# PIC32CX2051BZ62132 register map
Vendor: Microchip Technology; Series: PIC32CXBZ62; File version: 0
CPU: CM4 r0p1, little endian, MPU, FPU, 3 interrupt priority bits, 58 interrupts
Registers are 32-bit, read-write, reset 0x0 unless marked. A register's access mark holds for its fields unless they carry their own. Offsets are from the block's base; [hi:lo] are bit positions; {n}, {i} and the like mark numbered series; 'fields as' and 'values as' point back to an identical list.

## CFG
Base 0x44000000
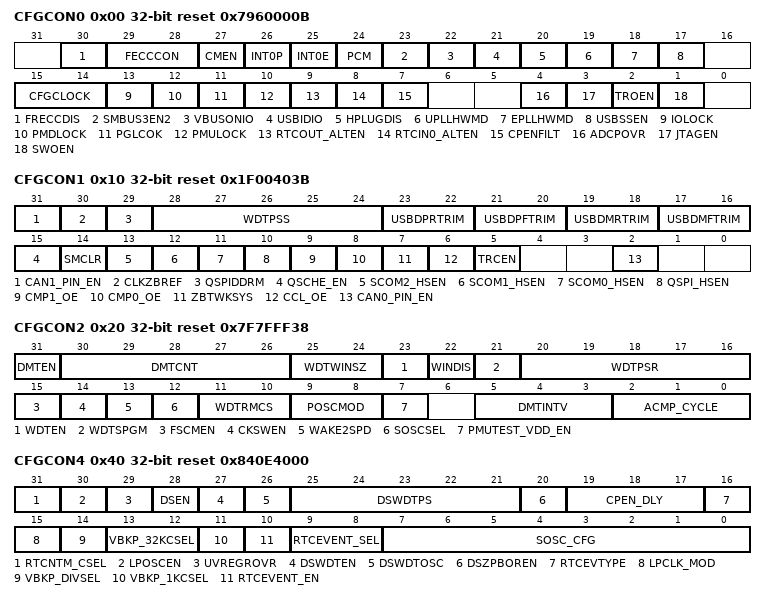
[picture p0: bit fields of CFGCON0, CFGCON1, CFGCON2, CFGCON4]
0x00 CFGCON0 reset 0x7960000B
  [30] FRECCDIS — Flex RAM ECC Control
  [29:28] FECCCON — Flash ECC Control
  [27] CMEN — SPA/DPA Countermeasures Enable
  [26] INT0P — INT0P Polarity
  [25] INT0E — INT0 Enable
  [24] PCM — PCHE I/D Cacheable Mode
  [23] SMBUS3EN2 — SMBus3 Enable for SERCOM2
  [22] VBUSONIO — USB VBUS_ON Selection bit
  [21] USBIDIO — USB USBID Selection bit
  [20] HPLUGDIS — Hot Plugging Disable (Outside Fuse Loading)
  [19] UPLLHWMD — UWPLL HW Control Mode for PWDN and RESET
  [18] EPLLHWMD — EWPLL HW Control Mode for PWDN and RESET
  [17] USBSSEN — USB Suspend Sleep Enable
  [15:14] CFGCLOCK — Configuration Register Lock
  [13] IOLOCK
  [12] PMDLOCK — Peripheral Module Disable (PMD) LOCK
  [11] PGLCOK — Permission Group LOCK
  [10] PMULOCK — PMU Controller Register LOCK
  [9] RTCOUT_ALTEN — RTCOUT Alternate Enable
  [8] RTCIN0_ALTEN — RTCIN0 Alternate Enable
  [7] CPENFILT — ADC CP Filter Enable
  [4] ADCPOVR — ADC Charge Pump Override
  [3] JTAGEN — JTAG Enable
  [2] TROEN — Trace Output Enable
  [1] SWOEN — SWO enable on 2-wire debug interface
{0x4+0x10*i} CFGCON{i}CLR (i=0..2) — Bit clear register
{0x8+0x10*i} CFGCON{i}SET (i=0..2) — Bit set register
{0xC+0x10*i} CFGCON{i}INV (i=0..2) — Bit invert register
0x10 CFGCON1 reset 0x1F00403B
  [31] CAN1_PIN_EN — CAN1 Pin Enable
  [30] CLKZBREF — External Reference Clock ZB Enable
  [29] QSPIDDRM — QSPI DDR Mode Clock Enable
  [28:24] WDTPSS — Watchdog Timer Post-scale Select Sleep
  [23:22] USBDPRTRIM — USB DP Rise Trim fuse bits
  [21:20] USBDPFTRIM — USB DP Fall Trim fuse bits
  [19:18] USBDMRTRIM — USB DM Rise Trim fuse bits
  [17:16] USBDMFTRIM — USB DM Fall Trim fuse bits
  [15] QSCHE_EN — QSPI Address Space Cache Attribute
  [14] SMCLR — Selects CRU handling of MCLR Control
  [13] SCOM2_HSEN — SERCOM2 Direct (High Speed) Pin Enable
  [12] SCOM1_HSEN — SERCOM1 Direct (High Speed) Pin Enable
  [11] SCOM0_HSEN — SERCOM0 Direct (High Speed) Pin Enable
  [10] QSPI_HSEN — QSPI (Direct) Enable
  [9] CMP1_OE — Analog Comparator-1 Output Enable
  [8] CMP0_OE — Analog Comparator-0 Output Enable
  [7] ZBTWKSYS — ZBT Subsystem External Wake-up source
  [6] CCL_OE — CCL Pads (via PPS) Output Enable
  [5] TRCEN — Trace Enable
  [2] CAN0_PIN_EN — CAN0 Pin Enable
0x20 CFGCON2 reset 0x7F7FFF38
  [31] DMTEN — Dead Man Timer Enable
  [30:26] DMTCNT — Dead Man Timer Count Select
  [25:24] WDTWINSZ — Watchdog Timer Window Size
  [23] WDTEN — Watchdog Timer Enable
  [22] WINDIS — Windowed Watchdog Timer Disable
  [21] WDTSPGM — Watchdog Timer Stop during Flash Programming
  [20:16] WDTPSR — Watchdog Timer Post-scale Select Run
  [15] FSCMEN — Fail-Safe Clock Monitor Enable
  [14] CKSWEN — Software Clock Switching Enable
  [13] WAKE2SPD — 2-Speed startup enabled in Sleep mode
  [12] SOSCSEL — SOSC Selection Configuration
  [11:10] WDTRMCS — WDT RUN Mode Clock Select
  [9:8] POSCMOD — Primary Oscillator Configuration
  [7] PMUTEST_VDD_EN — PMU Test Output or VDD/2 Enable via ADC IE12
  [5:3] DMTINTV — Dead Man Timer Count Window Interval
  [2:0] ACMP_CYCLE — AC SIB Comparator Result Wait Cycles
0x40 CFGCON4 reset 0x840E4000
  [31] RTCNTM_CSEL — RTC Counter Mode Clock Select
  [30] LPOSCEN — Low Power (Secondary) Oscillator Enable
  [29] UVREGROVR — ULPVREG Retention Mode Override
  [28] DSEN — Deep Sleep Bit Enable
  [27] DSWDTEN — Deep Sleep Watchdog Timer Enable
  [26] DSWDTOSC — Deep Sleep Watchdog Timer Reference Clock Select
  [25:21] DSWDTPS — Deep Sleep Watchdog Timer Postscale Select
  [20] DSZPBOREN — Deep Sleep Zero-Power BOR Enable
  [19:17] CPEN_DLY — Charge-pump ready digital delay
  [16] RTCEVTYPE — RTC Event Type
  [15] LPCLK_MOD — LPCLK modifier in counter/delay mode
  [14] VBKP_DIVSEL — VDDBUKPCORE LPCLK Clock Divider Selection
  [13:12] VBKP_32KCSEL — VDDBUKPCORE 32KHz clock source selection
  [11] VBKP_1KCSEL — VDDBUKPCORE LPCLK Clock Selection
  [10] RTCEVENT_EN — Pad Output Enable for MCHP legacy RTC event output
  [9:8] RTCEVENT_SEL — RTC Event Selection
  [7:0] SOSC_CFG — SOSC Configuration
0x44 CFGCON4CLR — Bit clear register
0x48 CFGCON4SET — Bit set register
0x4C CFGCON4INV — Bit invert register
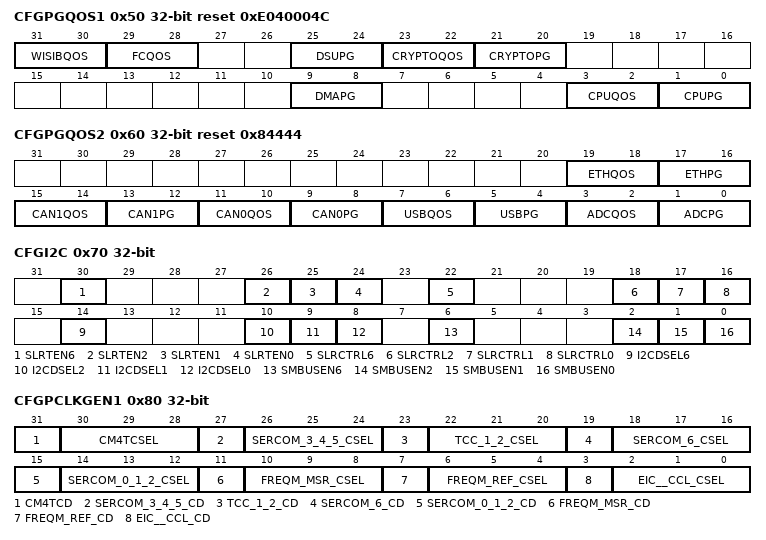
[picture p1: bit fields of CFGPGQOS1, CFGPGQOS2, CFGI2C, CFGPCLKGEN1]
0x50 CFGPGQOS1 reset 0xE040004C
  [31:30] WISIBQOS — Wireless SIB QOS Control
  [29:28] FCQOS — FC Controller QOS Control
  [25:24] DSUPG — DSU Permission Group
  [23:22] CRYPTOQOS — Crypto QOS Control
  [21:20] CRYPTOPG — Crypto Permission Group
  [9:8] DMAPG — DMA (Rd/Wr) Permission Group
  [3:2] CPUQOS — CPU I/D and System Bus QOS Control
  [1:0] CPUPG — CPU (Code) Permission Group
0x54 CFGPGQOS1CLR — Bit clear register
0x58 CFGPGQOS1SET — Bit set register
0x5C CFGPGQOS1INV — Bit invert register
0x60 CFGPGQOS2 reset 0x84444
  [19:18] ETHQOS — ETH QOS Control bits
  [17:16] ETHPG — ETH Permission Group
  [15:14] CAN1QOS — CAN1 QOS Control bits
  [13:12] CAN1PG — CAN1 Permission Group
  [11:10] CAN0QOS — CAN0 QOS Control bits
  [9:8] CAN0PG — CAN0 Permission Group
  [7:6] USBQOS — USB QOS Control bits
  [5:4] USBPG — USB Permission Group
  [3:2] ADCQOS — ADC QOS Control bits
  [1:0] ADCPG — ADC Permission Group
0x64 CFGPGQOS2CLR — Bit clear register
0x68 CFGPGQOS2SET — Bit set register
0x6C CFGPGQOS2INV — Bit invert register
0x70 CFGI2C
  [30] SLRTEN6 — SLRT Enable for SERCOM6
  [26] SLRTEN2 — SLRT Enable for SERCOM2
  [25] SLRTEN1 — SLRT Enable for SERCOM1
  [24] SLRTEN0 — SLRT Enable for SERCOM0
  [22] SLRCTRL6 — I2C Slew Rate Control for SERCOM6
  [18] SLRCTRL2 — I2C Slew Rate Control for SERCOM2
  [17] SLRCTRL1 — I2C Slew Rate Control for SERCOM1
  [16] SLRCTRL0 — I2C Slew Rate Control for SERCOM0
  [14] I2CDSEL6 — I2C Delay Select for SERCOM6
  [10] I2CDSEL2 — I2C Delay Select for SERCOM2
  [9] I2CDSEL1 — I2C Delay Select for SERCOM1
  [8] I2CDSEL0 — I2C Delay Select for SERCOM0
  [6] SMBUSEN6 — SMBus Enable for SERCOM6
  [2] SMBUSEN2 — SMBus Enable for SERCOM2
  [1] SMBUSEN1 — SMBus Enable for SERCOM1
  [0] SMBUSEN0 — SMBus Enable for SERCOM0
0x74 CFGI2CCLR — Bit clear register
0x78 CFGI2CSET — Bit set register
0x7C CFGI2CINV — Bit invert register
0x80 CFGPCLKGEN1
  [31] CM4TCD — CM4T Clock Disable
    1=ON (Enable PGCLK); 0=OFF (Disable PGCLK)
  [30:28] CM4TCSEL — CM4T Clock Selection
    0=NO_CLK (No Clock); {v}=REFO{v} (Reference Clock {v}) (v=1..6); 7=LPCLK (32 KHz Low Power Clock)
  [27] SERCOM_3_4_5_CD — SERCOM3/4/5 Clock Disable
    1=ON (Enable PGCLK); 0=OFF (Disable PGCLK)
  [26:24] SERCOM_3_4_5_CSEL — SERCOM3/4/5 Clock Selection
    values as CM4TCSEL
  [23] TCC_1_2_CD — TCC1/2 Clock Disable
    1=ON (Enable PGCLK); 0=OFF (Disable PGCLK)
  [22:20] TCC_1_2_CSEL — TCC1/2 Clock Selection
    values as CM4TCSEL
  [19] SERCOM_6_CD — SERCOM6 Clock Disable
    1=ON (Enable PGCLK); 0=OFF (Disable PGCLK)
  [18:16] SERCOM_6_CSEL — SERCOM6 Clock Selection
    values as CM4TCSEL
  [15] SERCOM_0_1_2_CD — SERCOM0/1/2 Clock Disable
    1=ON (Enable PGCLK); 0=OFF (Disable PGCLK)
  [14:12] SERCOM_0_1_2_CSEL — SERCOM0/1/2 Clock Selection
    values as CM4TCSEL
  [11] FREQM_MSR_CD — FREQMMC Clock Disable
    1=ON (Enable PGCLK); 0=OFF (Disable PGCLK)
  [10:8] FREQM_MSR_CSEL — FREQMMC Clock Selection
    values as CM4TCSEL
  [7] FREQM_REF_CD — FREQMRC Clock Disable
    1=ON (Enable PGCLK); 0=OFF (Disable PGCLK)
  [6:4] FREQM_REF_CSEL — FREQMRC Clock Selection
    values as CM4TCSEL
  [3] EIC__CCL_CD — EIC/CCL Clock Disable
    1=ON (Enable PGCLK); 0=OFF (Disable PGCLK)
  [2:0] EIC__CCL_CSEL — EIC/CCL Clock Selection
    values as CM4TCSEL
{0x74+0x10*i} CFGPCLKGEN{i}CLR (i=1..4) — Bit clear register
{0x78+0x10*i} CFGPCLKGEN{i}SET (i=1..4) — Bit set register
{0x7C+0x10*i} CFGPCLKGEN{i}INV (i=1..4) — Bit invert register
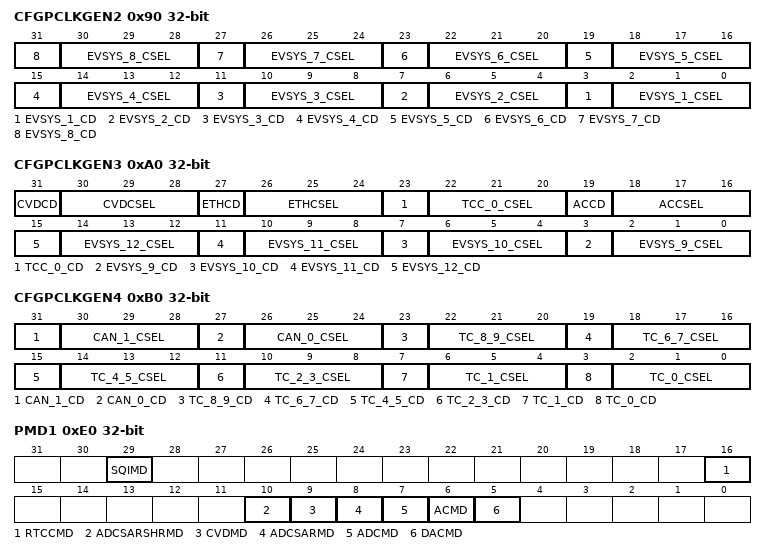
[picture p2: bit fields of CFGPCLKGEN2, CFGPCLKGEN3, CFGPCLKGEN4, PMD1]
0x90 CFGPCLKGEN2
  [4n-1] EVSYS_{n}_CD (n=1..8) — EVSYSC{n} Clock Disable
    1=ON (Enable PGCLK); 0=OFF (Disable PGCLK)
  [4n-2:4n-4] EVSYS_{n}_CSEL (n=1..8) — EVSYSC{n} Peripheral Clock Selection
    values as CFGPCLKGEN1.CM4TCSEL
0xA0 CFGPCLKGEN3
  [31] CVDCD — CVD Clock Disable
    1=ON (Enable PGCLK); 0=OFF (Disable PGCLK)
  [30:28] CVDCSEL — CVD Selection
    values as CFGPCLKGEN1.CM4TCSEL
  [27] ETHCD — Ethernet Clock Disable
    1=ON (Enable PGCLK); 0=OFF (Disable PGCLK)
  [26:24] ETHCSEL — Ethernet Clock Selection
    values as CFGPCLKGEN1.CM4TCSEL
  [23] TCC_0_CD — TCC0 Clock Disable
    1=ON (Enable PGCLK); 0=OFF (Disable PGCLK)
  [22:20] TCC_0_CSEL — TCC0 Peripheral Clock Selection
    values as CFGPCLKGEN1.CM4TCSEL
  [19] ACCD — AC Clock Disable
    1=ON (Enable PGCLK); 0=OFF (Disable PGCLK)
  [18:16] ACCSEL — AC Peripheral Clock Selection
    values as CFGPCLKGEN1.CM4TCSEL
  [4n-33] EVSYS_{n}_CD (n=9..12) — EVSYSC{n} Clock Disable
    1=ON (Enable PGCLK); 0=OFF (Disable PGCLK)
  [4n-34:4n-36] EVSYS_{n}_CSEL (n=9..12) — EVSYSC{n} Peripheral Clock Selection
    values as CFGPCLKGEN1.CM4TCSEL
0xB0 CFGPCLKGEN4
  [31] CAN_1_CD — CAN1 Clock Disable
    1=ON (Enable PGCLK); 0=OFF (Disable PGCLK)
  [30:28] CAN_1_CSEL — CAN1 Clock Selection
    values as CFGPCLKGEN1.CM4TCSEL
  [27] CAN_0_CD — CAN0 Clock Disable
    1=ON (Enable PGCLK); 0=OFF (Disable PGCLK)
  [26:24] CAN_0_CSEL — CAN0 Clock Selection
    values as CFGPCLKGEN1.CM4TCSEL
  [23] TC_8_9_CD — TC89 Clock Disable
    1=ON (Enable PGCLK); 0=OFF (Disable PGCLK)
  [22:20] TC_8_9_CSEL — TC89 Peripheral Clock Selection
    values as CFGPCLKGEN1.CM4TCSEL
  [19] TC_6_7_CD — TC67 Clock Disable
    1=ON (Enable PGCLK); 0=OFF (Disable PGCLK)
  [18:16] TC_6_7_CSEL — TC67 Peripheral Clock Selection
    values as CFGPCLKGEN1.CM4TCSEL
  [15] TC_4_5_CD — TC45 Clock Disable
    1=ON (Enable PGCLK); 0=OFF (Disable PGCLK)
  [14:12] TC_4_5_CSEL — TC45 Peripheral Clock Selection
    values as CFGPCLKGEN1.CM4TCSEL
  [11] TC_2_3_CD — TC23 Clock Disable
    1=ON (Enable PGCLK); 0=OFF (Disable PGCLK)
  [10:8] TC_2_3_CSEL — TC23 Peripheral Clock Selection
    values as CFGPCLKGEN1.CM4TCSEL
  [7] TC_1_CD — TC1 Clock Disable
    1=ON (Enable PGCLK); 0=OFF (Disable PGCLK)
  [6:4] TC_1_CSEL — TC1 Peripheral Clock Selection
    values as CFGPCLKGEN1.CM4TCSEL
  [3] TC_0_CD — TC0 Clock Disable
    1=ON (Enable PGCLK); 0=OFF (Disable PGCLK)
  [2:0] TC_0_CSEL — TC0 Peripheral Clock Selection
    values as CFGPCLKGEN1.CM4TCSEL
0xC0 USER_ID
  [15:0] USER_ID — User unique ID, readable using the SWD USER_ID instruction
0xC4 USER_IDCLR — Bit clear register
0xC8 USER_IDSET — Bit set register
0xCC USER_IDINV — Bit invert register
0xD0 SYSKEY
  [31:0] SYSKEY — System Key
0xE0 PMD1
  [29] SQIMD — SQI Module Disable
  [16] RTCCMD — RTCC Module Disable
  [10] ADCSARSHRMD — Shared ADC SAR Core Module Disable
  [9] CVDMD — ADC CVD Module Disable
  [8] ADCSARMD — ADC SAR Core Module Disable
  [7] ADCMD — ADC Controller Module Disable
  [6] ACMD — AC Module Disable
  [5] DACMD — DAC Module Disable
{0xD4+0x10*i} PMD{i}CLR (i=1..3) — Bit clear register
{0xD8+0x10*i} PMD{i}SET (i=1..3) — Bit set register
{0xDC+0x10*i} PMD{i}INV (i=1..3) — Bit invert register
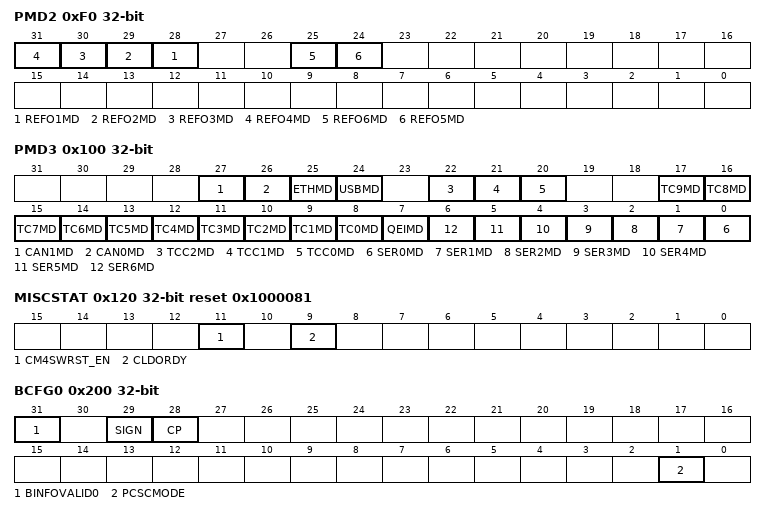
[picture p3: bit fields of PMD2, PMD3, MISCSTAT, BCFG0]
0xF0 PMD2
  [n+27] REFO{n}MD (n=1..4) — Reference (Clock) Out {n} Module Disable
  [25] REFO6MD — Reference (Clock) Out 6 Module Disable
  [24] REFO5MD — Reference (Clock) Out 5 Module Disable
0x100 PMD3
  [27] CAN1MD — CAN1 Module Disable
  [26] CAN0MD — CAN0 Module Disable
  [25] ETHMD — Ethernet Module Disable
  [24] USBMD — USB Module Disable
  [22] TCC2MD — TCC2 Module Disable
  [21] TCC1MD — TCC1 Module Disable
  [20] TCC0MD — TCC0 Module Disable
  [n+8] TC{n}MD (n=0..9) — TC{n} Module Disable
  [7] QEIMD — QEI Module Disable
  [n] SER{n}MD (n=0..6) — SERCOM{n} Module Disable
0x120 MISCSTAT reset 0x1000081
  [11] CM4SWRST_EN — CM4 SW Reset Enable
  [9] CLDORDY — CLDO Ready
0x160 ID ro — Device ID
0x200 BCFG0 ro
  [31] BINFOVALID0 — First 256-bit BCFG information Valid
  [29] SIGN — Flash SIGN
  [28] CP — Boot Code Protect
  [1] PCSCMODE — PCHE Single cache Mode
